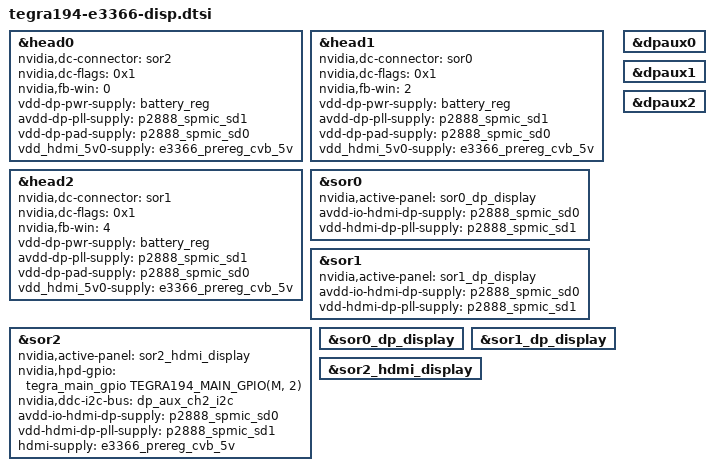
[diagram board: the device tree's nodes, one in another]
/*
 * Copyright (c) 2017-2020, NVIDIA CORPORATION.  All rights reserved.
 *
 * This program is free software; you can redistribute it and/or modify it
 * under the terms and conditions of the GNU General Public License,
 * version 2, as published by the Free Software Foundation.
 *
 * This program is distributed in the hope it will be useful, but WITHOUT
 * ANY WARRANTY; without even the implied warranty of MERCHANTABILITY or
 * FITNESS FOR A PARTICULAR PURPOSE.  See the GNU General Public License for
 * more details.
 *
 * You should have received a copy of the GNU General Public License
 * along with this program.  If not, see <http://www.gnu.org/licenses/>.
 */

/*
 * tegra194-e3366-disp.dtsi:
 */

/*
 * t194 galen mfg uses 3 display heads out of the 4 available on t194:
 *	fb0: Head0->SOR2->DPIM->HDMI
 *	fb1: Head1->SOR0->DPIM->DP0
 *	fb2: Head2->SOR1->DPIM->DP1
 * Each display head is assigned two windows each.
 */

#include "tegra194-fixed-regulator-e3366-1199.dtsi"
#include "tegra194-spmic-p2888-0001.dtsi"

&head0 {
	status = "okay";
	nvidia,dc-connector = <&sor2>; // nvdisp-init only
	nvidia,dc-flags = <0x1>; // nvdisp-init only
	nvidia,fb-win = <0>; // nvdisp-init only
	vdd-dp-pwr-supply = <&battery_reg>; // nvdisp-init only
	avdd-dp-pll-supply = <&p2888_spmic_sd1>; // nvdisp-init only
	vdd-dp-pad-supply = <&p2888_spmic_sd0>;
	vdd_hdmi_5v0-supply = <&e3366_prereg_cvb_5v>; // nvdisp-init only
};

&head1 {
	status = "okay";
	nvidia,dc-connector = <&sor0>; // nvdisp-init only
	nvidia,dc-flags = <0x1>; // nvdisp-init only
	nvidia,fb-win = <2>; // nvdisp-init only
	vdd-dp-pwr-supply = <&battery_reg>; // nvdisp-init only
	avdd-dp-pll-supply = <&p2888_spmic_sd1>; // nvdisp-init only
	vdd-dp-pad-supply = <&p2888_spmic_sd0>;
	vdd_hdmi_5v0-supply = <&e3366_prereg_cvb_5v>; // nvdisp-init only
};

&head2 {
	status = "okay";
	nvidia,dc-connector = <&sor1>; // nvdisp-init only
	nvidia,dc-flags = <0x1>; // nvdisp-init only
	nvidia,fb-win = <4>; // nvdisp-init only
	vdd-dp-pwr-supply = <&battery_reg>; // nvdisp-init only
	avdd-dp-pll-supply = <&p2888_spmic_sd1>; // nvdisp-init only
	vdd-dp-pad-supply = <&p2888_spmic_sd0>;
	vdd_hdmi_5v0-supply = <&e3366_prereg_cvb_5v>; // nvdisp-init only
};

&sor0 {
	status = "okay";
	nvidia,active-panel = <&sor0_dp_display>;
	avdd-io-hdmi-dp-supply = <&p2888_spmic_sd0>;
	vdd-hdmi-dp-pll-supply = <&p2888_spmic_sd1>;
};

&sor1 {
	status = "okay";
	nvidia,active-panel = <&sor1_dp_display>;
	avdd-io-hdmi-dp-supply = <&p2888_spmic_sd0>;
	vdd-hdmi-dp-pll-supply = <&p2888_spmic_sd1>;
};

&sor2 {
	status = "okay";
	nvidia,active-panel = <&sor2_hdmi_display>;
	nvidia,hpd-gpio = <&tegra_main_gpio TEGRA194_MAIN_GPIO(M, 2) GPIO_ACTIVE_HIGH>;
	nvidia,ddc-i2c-bus = <&dp_aux_ch2_i2c>;
	avdd-io-hdmi-dp-supply = <&p2888_spmic_sd0>;
	vdd-hdmi-dp-pll-supply = <&p2888_spmic_sd1>;
	hdmi-supply = <&e3366_prereg_cvb_5v>;
};

&sor0_dp_display {
	status = "okay";
};

&sor1_dp_display {
	status = "okay";
};

&sor2_hdmi_display {
	status = "okay";
};

&dpaux0 {
	status = "okay";
};

&dpaux1 {
	status = "okay";
};

&dpaux2 {
	status = "okay";
};
